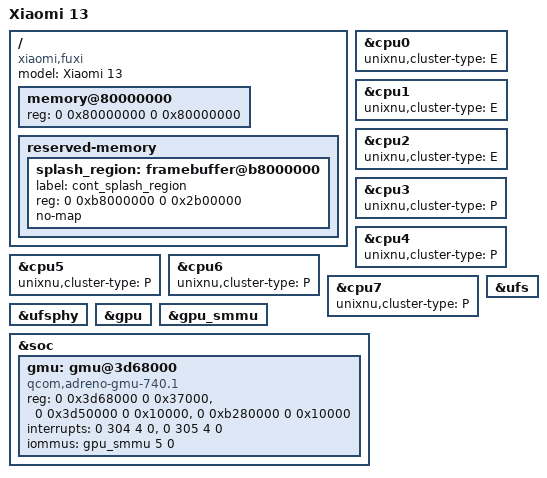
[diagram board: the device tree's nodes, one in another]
/dts-v1/;
/include/ "sm8550.dtsi"

/ {
    model = "Xiaomi 13";
    compatible = "xiaomi,fuxi", "qcom,sm8550";

    memory@80000000 {
        device_type = "memory";
        reg = <0 0x80000000 0 0x80000000>;
    };

    reserved-memory {
        #address-cells = <2>;
        #size-cells = <2>;
        ranges;

        splash_region: framebuffer@b8000000 {
            label = "cont_splash_region";
            reg = <0 0xb8000000 0 0x2b00000>;
            no-map;
        };
    };
};

&cpu0 { unixnu,cluster-type = "E"; };
&cpu1 { unixnu,cluster-type = "E"; };
&cpu2 { unixnu,cluster-type = "E"; };
&cpu3 { unixnu,cluster-type = "P"; };
&cpu4 { unixnu,cluster-type = "P"; };
&cpu5 { unixnu,cluster-type = "P"; };
&cpu6 { unixnu,cluster-type = "P"; };
&cpu7 { unixnu,cluster-type = "P"; };

&ufs { status = "okay"; };
&ufsphy { status = "okay"; };
&gpu { status = "okay"; };
&gpu_smmu { status = "okay"; };

&soc {
    /delete-node/ gmu@3d6a000;

    gmu: gmu@3d68000 {
        compatible = "qcom,adreno-gmu-740.1", "qcom,adreno-gmu";
        reg = <0 0x3d68000 0 0x37000>, <0 0x3d50000 0 0x10000>, <0 0xb280000 0 0x10000>;
        reg-names = "gmu", "rscc", "gmu_pdc";
        interrupts = <0 304 4 0>, <0 305 4 0>;
        interrupt-names = "hfi", "gmu";
        iommus = <&gpu_smmu 5 0>;
        status = "okay";
    };
};
